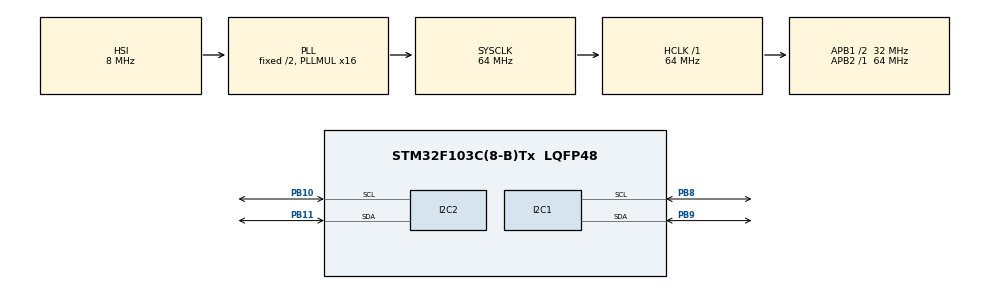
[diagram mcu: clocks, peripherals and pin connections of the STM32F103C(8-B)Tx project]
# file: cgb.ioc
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Mcu.Family=STM32F1
Mcu.Name=STM32F103C(8-B)Tx
Mcu.Package=LQFP48
NVIC.PriorityGroup=NVIC_PRIORITYGROUP_4
PA13.Mode=Serial_Wire
PA13.Signal=SYS_JTMS-SWDIO
PA14.Mode=Serial_Wire
PA14.Signal=SYS_JTCK-SWCLK
PB10.Mode=I2C
PB10.Signal=I2C2_SCL
PB11.Mode=I2C
PB11.Signal=I2C2_SDA
PB8.Mode=I2C
PB8.Signal=I2C1_SCL
PB9.Mode=I2C
PB9.Signal=I2C1_SDA
ProjectManager.HeapSize=0x200
ProjectManager.StackSize=0x400
ProjectManager.TargetToolchain=MDK-ARM V5.32
RCC.AHBFreq_Value=64000000
RCC.APB1CLKDivider=RCC_HCLK_DIV2
RCC.APB1Freq_Value=32000000
RCC.APB1TimFreq_Value=64000000
RCC.APB2Freq_Value=64000000
RCC.APB2TimFreq_Value=64000000
RCC.HCLKFreq_Value=64000000
RCC.PLLMUL=RCC_PLL_MUL16
RCC.SYSCLKFreq_VALUE=64000000
RCC.SYSCLKSource=RCC_SYSCLKSOURCE_PLLCLK
RCC.USBFreq_Value=64000000
board=custom

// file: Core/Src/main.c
/* USER CODE BEGIN Header */
/**
  ******************************************************************************
  * @file           : main.c
  * @brief          : Main program body
  ******************************************************************************
  * @attention
  *
  * Copyright (c) 2025 STMicroelectronics.
  * All rights reserved.
  *
  * This software is licensed under terms that can be found in the LICENSE file
  * in the root directory of this software component.
  * If no LICENSE file comes with this software, it is provided AS-IS.
  *
  ******************************************************************************
  */
/* USER CODE END Header */
#include "main.h"
#include "i2c.h"
#include "gpio.h"
#include "ssd1306.h"
#include "bh1750.h"
#include <stdio.h>

void SystemClock_Config(void);

/* USER CODE BEGIN 0 */
char buf[16];
/* USER CODE END 0 */

int main(void)
{

  /* MCU Configuration--------------------------------------------------------*/

  /* Reset of all peripherals, Initializes the Flash interface and the Systick. */
  HAL_Init();

  /* Configure the system clock */
  SystemClock_Config();

  /* Initialize all configured peripherals */
  MX_GPIO_Init();
  MX_I2C1_Init();
  MX_I2C2_Init();
  /* USER CODE BEGIN 2 */
  SSD1306_Init();
  BH1750_Init();
  /* USER CODE END 2 */

  /* Infinite loop */
  while (1)
  {
        float lux = BH1750_ReadLight();
        snprintf(buf, sizeof(buf), "Lux: %.1f", lux);
        SSD1306_Clear();
        SSD1306_ShowString(0, 0, buf);
        HAL_Delay(500);
  }
}

void SystemClock_Config(void)
{
  RCC_OscInitTypeDef RCC_OscInitStruct = {0};
  RCC_ClkInitTypeDef RCC_ClkInitStruct = {0};

  /** Initializes the RCC Oscillators according to the specified parameters
  * in the RCC_OscInitTypeDef structure.
  */
  RCC_OscInitStruct.OscillatorType = RCC_OSCILLATORTYPE_HSI;
  RCC_OscInitStruct.HSIState = RCC_HSI_ON;
  RCC_OscInitStruct.HSICalibrationValue = RCC_HSICALIBRATION_DEFAULT;
  RCC_OscInitStruct.PLL.PLLState = RCC_PLL_ON;
  RCC_OscInitStruct.PLL.PLLSource = RCC_PLLSOURCE_HSI_DIV2;
  RCC_OscInitStruct.PLL.PLLMUL = RCC_PLL_MUL16;
  if (HAL_RCC_OscConfig(&RCC_OscInitStruct) != HAL_OK)
  {
    Error_Handler();
  }

  /** Initializes the CPU, AHB and APB buses clocks
  */
  RCC_ClkInitStruct.ClockType = RCC_CLOCKTYPE_HCLK|RCC_CLOCKTYPE_SYSCLK
                              |RCC_CLOCKTYPE_PCLK1|RCC_CLOCKTYPE_PCLK2;
  RCC_ClkInitStruct.SYSCLKSource = RCC_SYSCLKSOURCE_PLLCLK;
  RCC_ClkInitStruct.AHBCLKDivider = RCC_SYSCLK_DIV1;
  RCC_ClkInitStruct.APB1CLKDivider = RCC_HCLK_DIV2;
  RCC_ClkInitStruct.APB2CLKDivider = RCC_HCLK_DIV1;

  if (HAL_RCC_ClockConfig(&RCC_ClkInitStruct, FLASH_LATENCY_2) != HAL_OK)
  {
    Error_Handler();
  }
}

void Error_Handler(void)
{
  __disable_irq();
  while (1)
  {
  }
}
